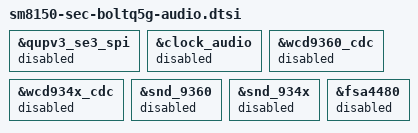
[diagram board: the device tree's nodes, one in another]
/* Copyright (c) 2016-2017, The Linux Foundation. All rights reserved.
 *
 * This program is free software; you can redistribute it and/or modify
 * it under the terms of the GNU General Public License version 2 and
 * only version 2 as published by the Free Software Foundation.
 *
 * This program is distributed in the hope that it will be useful,
 * but WITHOUT ANY WARRANTY; without even the implied warranty of
 * MERCHANTABILITY or FITNESS FOR A PARTICULAR PURPOSE.  See the
 * GNU General Public License for more details.
 */

#include "../qcom/sm8150-audio-overlay.dtsi"

/{
};

&qupv3_se3_spi {
	status = "disabled";
};

&clock_audio {
	status = "disabled";
};

&wcd9360_cdc {
	status = "disabled";
};

&wcd934x_cdc {
	status = "disabled";
};

&snd_9360 {
	status = "disabled";
};

&snd_934x {
	status = "disabled";
};

&fsa4480 {
	status = "disabled";
};
